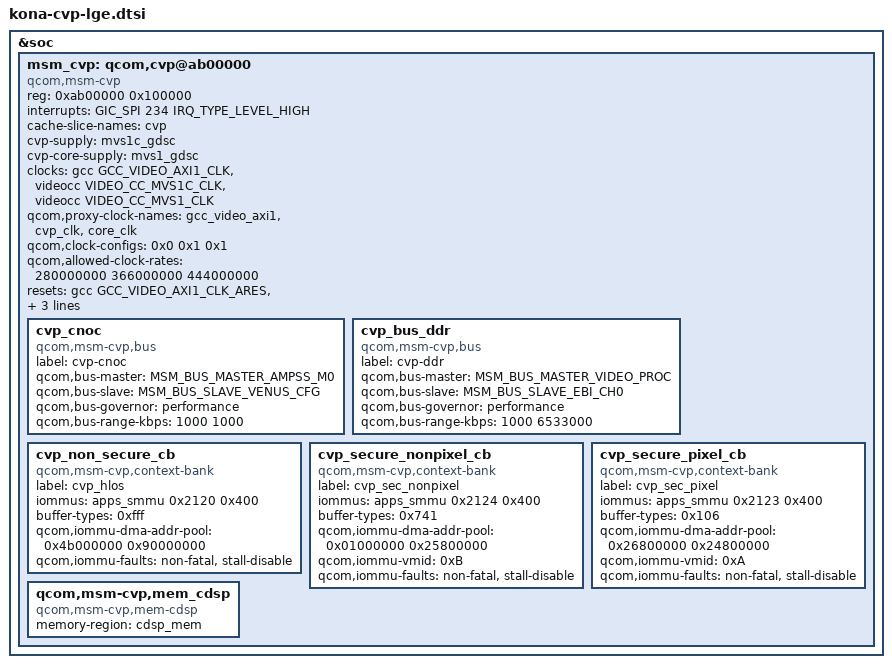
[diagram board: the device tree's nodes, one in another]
// SPDX-License-Identifier: GPL-2.0-only
/*
 * timelm: QC/LG 4.19 kona-cvp.dtsi (android_kernel_lge_sm8250
 * arch/arm64/boot/dts/vendor/qcom/kona-cvp.dtsi) for the forward-ported
 * msm-cvp.ko (android_kernel_lge_sm8250-modules/qcom/opensource/cvp-lge).
 *
 * Changes from stock: &clock_gcc -> &gcc, &clock_videocc -> &videocc
 * (5.15 qcom,gcc-sm8250.h / qcom,videocc-sm8250.h, same names), and
 * memory-region for the firmware (4.19 qcom,cvpss@abb0000 PIL used
 * pil_cvp_mem, PAS 26).  The qcom,msm-bus ids are translated to ICC in
 * timelm_msm_bus_icc.c; mvs1/mvs1c_gdsc are the 5.15 kona.dtsi regulators.
 */
#include <dt-bindings/interrupt-controller/arm-gic.h>
#include <dt-bindings/msm/msm-bus-ids.h>
#include <dt-bindings/clock/qcom,gcc-sm8250.h>
#include <dt-bindings/clock/qcom,videocc-sm8250.h>

&soc {
	msm_cvp: qcom,cvp@ab00000 {
		compatible = "qcom,msm-cvp", "qcom,kona-cvp";
		status = "ok";
		reg = <0xab00000 0x100000>;
		interrupts = <GIC_SPI 234 IRQ_TYPE_LEVEL_HIGH>;

		/* LLCC Cache */
		cache-slice-names = "cvp";

		/* Supply */
		cvp-supply = <&mvs1c_gdsc>;
		cvp-core-supply = <&mvs1_gdsc>;

		/* Clocks */
		clock-names = "gcc_video_axi1", "cvp_clk", "core_clk";
		clocks = <&gcc GCC_VIDEO_AXI1_CLK>,
			<&videocc VIDEO_CC_MVS1C_CLK>,
			<&videocc VIDEO_CC_MVS1_CLK>;
		qcom,proxy-clock-names = "gcc_video_axi1",
			"cvp_clk", "core_clk";

		/* V2 clock frequency plan */
		qcom,clock-configs = <0x0 0x1 0x1>;
		qcom,allowed-clock-rates = <280000000 366000000 444000000>;

		resets = <&gcc GCC_VIDEO_AXI1_CLK_ARES>,
			<&videocc VIDEO_CC_MVS1C_CLK_ARES>;
		reset-names = "cvp_axi_reset", "cvp_core_reset";

		qcom,reg-presets = <0xB0088 0x0>;

		/* timelm: cvpss.mdt is loaded here (4.19 pil_cvp_mem, PAS 26) */
		memory-region = <&pil_cvp_mem>;

		/* Buses */
		cvp_cnoc {
			compatible = "qcom,msm-cvp,bus";
			label = "cvp-cnoc";
			qcom,bus-master = <MSM_BUS_MASTER_AMPSS_M0>;
			qcom,bus-slave = <MSM_BUS_SLAVE_VENUS_CFG>;
			qcom,bus-governor = "performance";
			qcom,bus-range-kbps = <1000 1000>;
		};

		cvp_bus_ddr {
			compatible = "qcom,msm-cvp,bus";
			label = "cvp-ddr";
			qcom,bus-master = <MSM_BUS_MASTER_VIDEO_PROC>;
			qcom,bus-slave = <MSM_BUS_SLAVE_EBI_CH0>;
			qcom,bus-governor = "performance";
			qcom,bus-range-kbps = <1000 6533000>;
		};

		/* MMUs */
		cvp_non_secure_cb {
			compatible = "qcom,msm-cvp,context-bank";
			label = "cvp_hlos";
			iommus =
				<&apps_smmu 0x2120 0x400>;
			buffer-types = <0xfff>;
			qcom,iommu-dma-addr-pool = <0x4b000000 0x90000000>;
			qcom,iommu-faults = "non-fatal", "stall-disable";
		};

		cvp_secure_nonpixel_cb {
			compatible = "qcom,msm-cvp,context-bank";
			label = "cvp_sec_nonpixel";
			iommus =
				<&apps_smmu 0x2124 0x400>;
			buffer-types = <0x741>;
			qcom,iommu-dma-addr-pool = <0x01000000 0x25800000>;
			qcom,iommu-vmid = <0xB>;
			qcom,iommu-faults = "non-fatal", "stall-disable";
		};

		cvp_secure_pixel_cb {
			compatible = "qcom,msm-cvp,context-bank";
			label = "cvp_sec_pixel";
			iommus =
				<&apps_smmu 0x2123 0x400>;
			buffer-types = <0x106>;
			qcom,iommu-dma-addr-pool = <0x26800000 0x24800000>;
			qcom,iommu-vmid = <0xA>;
			qcom,iommu-faults = "non-fatal", "stall-disable";
		};

		/* Memory Heaps */
		qcom,msm-cvp,mem_cdsp {
			compatible = "qcom,msm-cvp,mem-cdsp";
			memory-region = <&cdsp_mem>;
		};
	};
};
